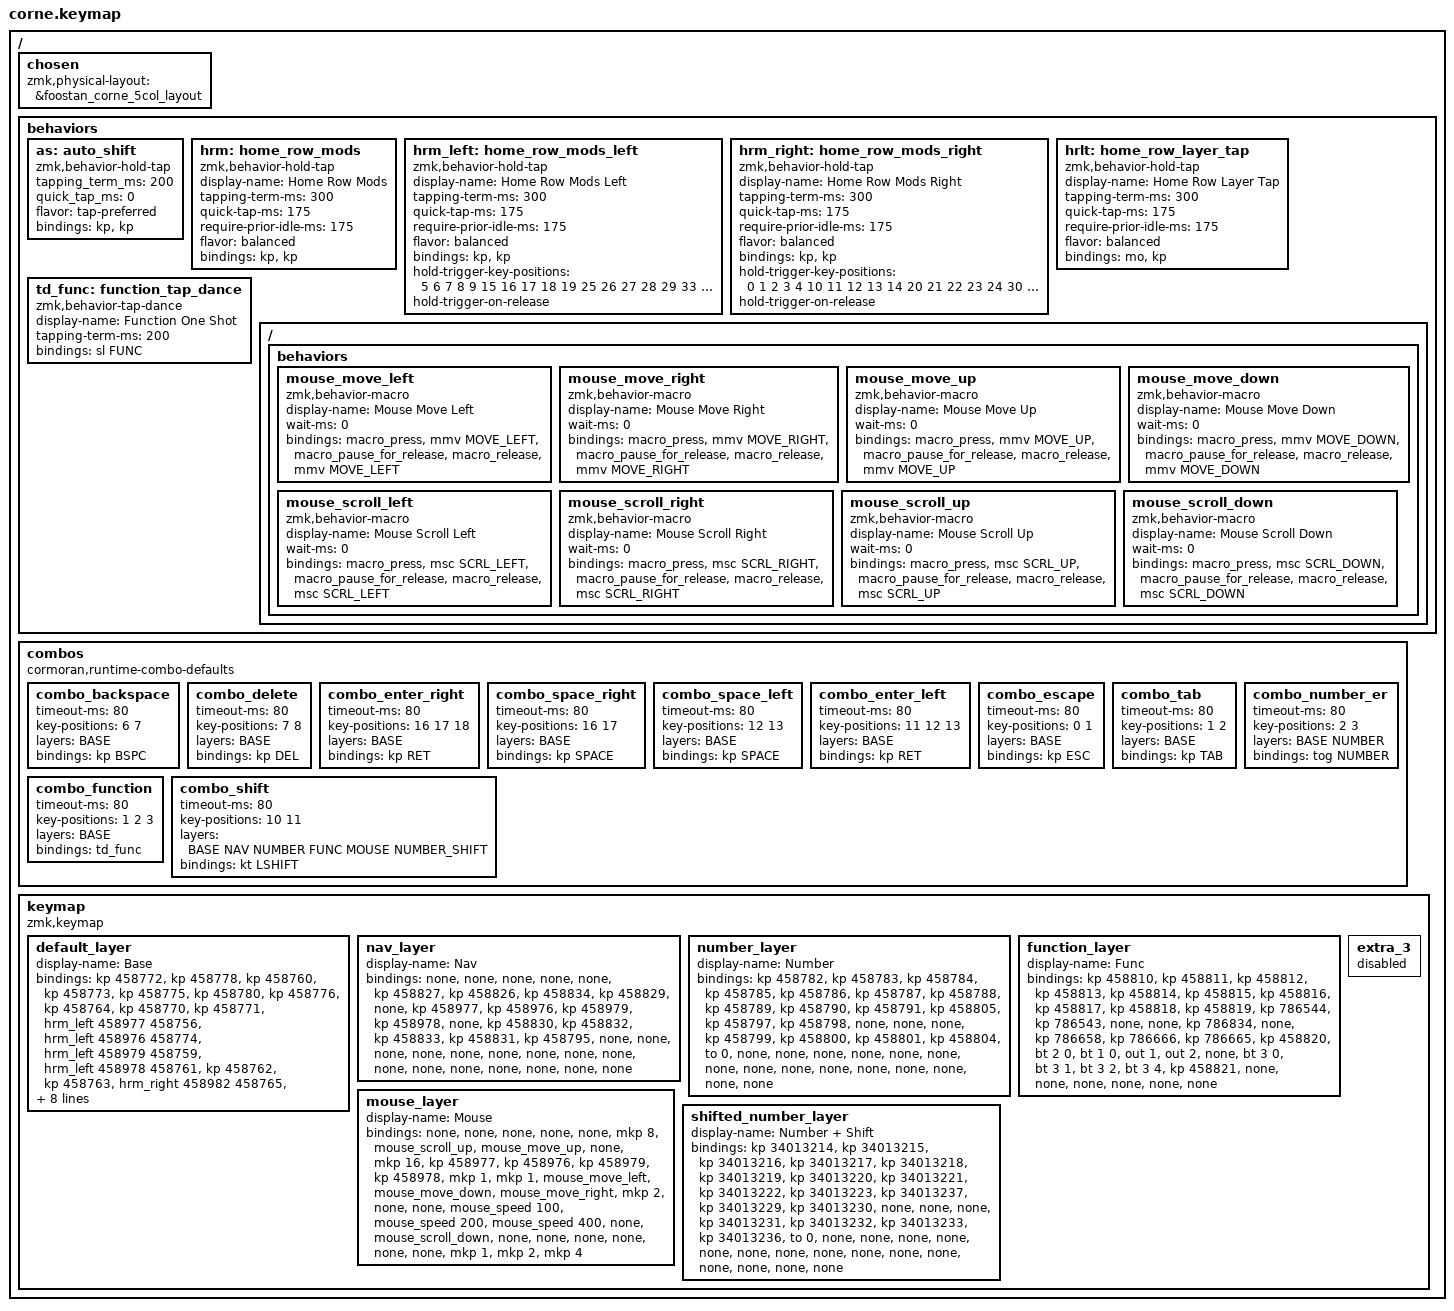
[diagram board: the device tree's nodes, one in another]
/*
 * Copyright (c) 2020 The ZMK Contributors
 *
 * SPDX-License-Identifier: MIT
 */

#include <behaviors.dtsi>
#include <dt-bindings/zmk/keys.h>
#include <dt-bindings/zmk/bt.h>
#include <dt-bindings/zmk/pointing.h>
#include <dt-bindings/zmk/outputs.h>
#include <behaviors/mouse_speed.dtsi>
#include <behaviors/runtime_macro.dtsi>

#define BASE 0
#define NAV 1
#define NUMBER 2
#define FUNC 3
#define MOUSE 4
#define NUMBER_SHIFT 5

#define AS(keycode) &as LS(keycode) keycode

/ {
    chosen {
        zmk,physical-layout = &foostan_corne_5col_layout;
    };

    behaviors {
        as: auto_shift {
            compatible = "zmk,behavior-hold-tap";
            #binding-cells = <2>;
            tapping_term_ms = <200>;
            quick_tap_ms = <0>;
            flavor = "tap-preferred";
            bindings = <&kp>, <&kp>;
        };

        hrm: home_row_mods {
            compatible = "zmk,behavior-hold-tap";
            #binding-cells = <2>;
            display-name = "Home Row Mods";
            tapping-term-ms = <300>;
            quick-tap-ms = <175>;
            require-prior-idle-ms = <175>;
            flavor = "balanced";
            bindings = <&kp>, <&kp>;
        };

        hrm_left: home_row_mods_left {
            compatible = "zmk,behavior-hold-tap";
            #binding-cells = <2>;
            display-name = "Home Row Mods Left";
            tapping-term-ms = <300>;
            quick-tap-ms = <175>;
            require-prior-idle-ms = <175>;
            flavor = "balanced";
            bindings = <&kp>, <&kp>;
            hold-trigger-key-positions = <5 6 7 8 9 15 16 17 18 19 25 26 27 28 29 33 34 35>;
            hold-trigger-on-release;
        };

        hrm_right: home_row_mods_right {
            compatible = "zmk,behavior-hold-tap";
            #binding-cells = <2>;
            display-name = "Home Row Mods Right";
            tapping-term-ms = <300>;
            quick-tap-ms = <175>;
            require-prior-idle-ms = <175>;
            flavor = "balanced";
            bindings = <&kp>, <&kp>;
            hold-trigger-key-positions = <0 1 2 3 4 10 11 12 13 14 20 21 22 23 24 30 31 32>;
            hold-trigger-on-release;
        };

        hrlt: home_row_layer_tap {
            compatible = "zmk,behavior-hold-tap";
            #binding-cells = <2>;
            display-name = "Home Row Layer Tap";
            tapping-term-ms = <300>;
            quick-tap-ms = <175>;
            require-prior-idle-ms = <175>;
            flavor = "balanced";
            bindings = <&mo>, <&kp>;
        };

        td_func: function_tap_dance {
            compatible = "zmk,behavior-tap-dance";
            #binding-cells = <0>;
            display-name = "Function One Shot";
            tapping-term-ms = <200>;
            bindings = <&sl FUNC>;
        };

        // Runtime format v1 cannot represent pause-for-release; retain native movement.
        ZMK_MACRO(mouse_move_left,
            display-name = "Mouse Move Left";
            wait-ms = <0>;
            bindings = <&macro_press &mmv MOVE_LEFT>, <&macro_pause_for_release>, <&macro_release &mmv MOVE_LEFT>;
        )
        ZMK_MACRO(mouse_move_right,
            display-name = "Mouse Move Right";
            wait-ms = <0>;
            bindings = <&macro_press &mmv MOVE_RIGHT>, <&macro_pause_for_release>, <&macro_release &mmv MOVE_RIGHT>;
        )
        ZMK_MACRO(mouse_move_up,
            display-name = "Mouse Move Up";
            wait-ms = <0>;
            bindings = <&macro_press &mmv MOVE_UP>, <&macro_pause_for_release>, <&macro_release &mmv MOVE_UP>;
        )
        ZMK_MACRO(mouse_move_down,
            display-name = "Mouse Move Down";
            wait-ms = <0>;
            bindings = <&macro_press &mmv MOVE_DOWN>, <&macro_pause_for_release>, <&macro_release &mmv MOVE_DOWN>;
        )
        ZMK_MACRO(mouse_scroll_left,
            display-name = "Mouse Scroll Left";
            wait-ms = <0>;
            bindings = <&macro_press &msc SCRL_LEFT>, <&macro_pause_for_release>, <&macro_release &msc SCRL_LEFT>;
        )
        ZMK_MACRO(mouse_scroll_right,
            display-name = "Mouse Scroll Right";
            wait-ms = <0>;
            bindings = <&macro_press &msc SCRL_RIGHT>, <&macro_pause_for_release>, <&macro_release &msc SCRL_RIGHT>;
        )
        ZMK_MACRO(mouse_scroll_up,
            display-name = "Mouse Scroll Up";
            wait-ms = <0>;
            bindings = <&macro_press &msc SCRL_UP>, <&macro_pause_for_release>, <&macro_release &msc SCRL_UP>;
        )
        ZMK_MACRO(mouse_scroll_down,
            display-name = "Mouse Scroll Down";
            wait-ms = <0>;
            bindings = <&macro_press &msc SCRL_DOWN>, <&macro_pause_for_release>, <&macro_release &msc SCRL_DOWN>;
        )
    };

    combos {
        compatible = "cormoran,runtime-combo-defaults";

        combo_backspace {
            timeout-ms = <80>;
            key-positions = <6 7>;
            layers = <BASE>;
            bindings = <&kp BSPC>;
        };

        combo_delete {
            timeout-ms = <80>;
            key-positions = <7 8>;
            layers = <BASE>;
            bindings = <&kp DEL>;
        };

        combo_enter_right {
            timeout-ms = <80>;
            key-positions = <16 17 18>;
            layers = <BASE>;
            bindings = <&kp RET>;
        };

        combo_space_right {
            timeout-ms = <80>;
            key-positions = <16 17>;
            layers = <BASE>;
            bindings = <&kp SPACE>;
        };

        combo_space_left {
            timeout-ms = <80>;
            key-positions = <12 13>;
            layers = <BASE>;
            bindings = <&kp SPACE>;
        };

        combo_enter_left {
            timeout-ms = <80>;
            key-positions = <11 12 13>;
            layers = <BASE>;
            bindings = <&kp RET>;
        };

        combo_escape {
            timeout-ms = <80>;
            key-positions = <0 1>;
            layers = <BASE>;
            bindings = <&kp ESC>;
        };

        combo_tab {
            timeout-ms = <80>;
            key-positions = <1 2>;
            layers = <BASE>;
            bindings = <&kp TAB>;
        };

        combo_number_er {
            timeout-ms = <80>;
            key-positions = <2 3>;
            layers = <BASE NUMBER>;
            bindings = <&tog NUMBER>;
        };

        combo_function {
            timeout-ms = <80>;
            key-positions = <1 2 3>;
            layers = <BASE>;
            bindings = <&td_func>;
        };

        combo_shift {
            timeout-ms = <80>;
            key-positions = <10 11>;
            layers = <BASE NAV NUMBER FUNC MOUSE NUMBER_SHIFT>;
            bindings = <&kt LSHIFT>;
        };
    };

        keymap {
                compatible = "zmk,keymap";

                default_layer {
                    display-name = "Base";
                    bindings = <
                        &kp 458772
                        &kp 458778
                        &kp 458760
                        &kp 458773
                        &kp 458775
                        &kp 458780
                        &kp 458776
                        &kp 458764
                        &kp 458770
                        &kp 458771
                        &hrm_left 458977 458756
                        &hrm_left 458976 458774
                        &hrm_left 458979 458759
                        &hrm_left 458978 458761
                        &kp 458762
                        &kp 458763
                        &hrm_right 458982 458765
                        &hrm_right 458983 458766
                        &hrm_right 458980 458767
                        &hrm_right 458981 458803
                        &kp 458781
                        &kp 458779
                        &kp 458758
                        &lt 2 458777
                        &kp 458757
                        &kp 458769
                        &lt 2 458768
                        &kp 458806
                        &kp 458807
                        &kp 458808
                        &lt 3 458793
                        &lt 1 458795
                        &lt 4 458796
                        &lt 4 458794
                        &lt 1 458792
                        &lt 3 458828
                    >;
                };
                nav_layer {
                    display-name = "Nav";
                    bindings = <
                        &none
                        &none
                        &none
                        &none
                        &none
                        &kp 458827
                        &kp 458826
                        &kp 458834
                        &kp 458829
                        &none
                        &kp 458977
                        &kp 458976
                        &kp 458979
                        &kp 458978
                        &none
                        &kp 458830
                        &kp 458832
                        &kp 458833
                        &kp 458831
                        &kp 458795
                        &none
                        &none
                        &none
                        &none
                        &none
                        &none
                        &none
                        &none
                        &none
                        &none
                        &none
                        &none
                        &none
                        &none
                        &none
                        &none
                    >;
                };
                number_layer {
                    display-name = "Number";
                    bindings = <
                        &kp 458782
                        &kp 458783
                        &kp 458784
                        &kp 458785
                        &kp 458786
                        &kp 458787
                        &kp 458788
                        &kp 458789
                        &kp 458790
                        &kp 458791
                        &kp 458805
                        &kp 458797
                        &kp 458798
                        &none
                        &none
                        &none
                        &kp 458799
                        &kp 458800
                        &kp 458801
                        &kp 458804
                        &to 0
                        &none
                        &none
                        &none
                        &none
                        &none
                        &none
                        &none
                        &none
                        &none
                        &none
                        &none
                        &none
                        &none
                        &none
                        &none
                    >;
                };
                function_layer {
                    display-name = "Func";
                    bindings = <
                        &kp 458810
                        &kp 458811
                        &kp 458812
                        &kp 458813
                        &kp 458814
                        &kp 458815
                        &kp 458816
                        &kp 458817
                        &kp 458818
                        &kp 458819
                        &kp 786544
                        &kp 786543
                        &none
                        &none
                        &kp 786834
                        &none
                        &kp 786658
                        &kp 786666
                        &kp 786665
                        &kp 458820
                        &bt 2 0
                        &bt 1 0
                        &out 1
                        &out 2
                        &none
                        &bt 3 0
                        &bt 3 1
                        &bt 3 2
                        &bt 3 4
                        &kp 458821
                        &none
                        &none
                        &none
                        &none
                        &none
                        &none
                    >;
                };
                mouse_layer {
                    display-name = "Mouse";
                    bindings = <
                        &none
                        &none
                        &none
                        &none
                        &none
                        &mkp 8
                        &mouse_scroll_up
                        &mouse_move_up
                        &none
                        &mkp 16
                        &kp 458977
                        &kp 458976
                        &kp 458979
                        &kp 458978
                        &mkp 1
                        &mkp 1
                        &mouse_move_left
                        &mouse_move_down
                        &mouse_move_right
                        &mkp 2
                        &none
                        &none
                        &mouse_speed 100
                        &mouse_speed 200
                        &mouse_speed 400
                        &none
                        &mouse_scroll_down
                        &none
                        &none
                        &none
                        &none
                        &none
                        &none
                        &mkp 1
                        &mkp 2
                        &mkp 4
                    >;
                };
                shifted_number_layer {
                    display-name = "Number + Shift";
                    bindings = <
                        &kp 34013214
                        &kp 34013215
                        &kp 34013216
                        &kp 34013217
                        &kp 34013218
                        &kp 34013219
                        &kp 34013220
                        &kp 34013221
                        &kp 34013222
                        &kp 34013223
                        &kp 34013237
                        &kp 34013229
                        &kp 34013230
                        &none
                        &none
                        &none
                        &kp 34013231
                        &kp 34013232
                        &kp 34013233
                        &kp 34013236
                        &to 0
                        &none
                        &none
                        &none
                        &none
                        &none
                        &none
                        &none
                        &none
                        &none
                        &none
                        &none
                        &none
                        &none
                        &none
                        &none
                    >;
                };

                extra_3 {
                        status = "reserved";
                };
        };
};
